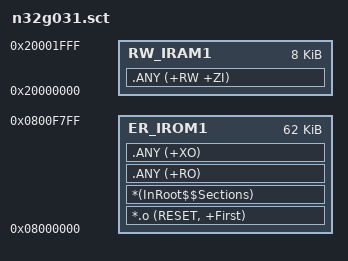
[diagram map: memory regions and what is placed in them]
; N32G031 64KB Flash 0x08000000‑0x0800FFFF
; 主程序使用：0x08000000 ~ 0x0800F7FF (62KB)
; 参数保留页：0x0800F800 ~ 0x0800FFFF （2KB，禁止放代码）
LR_IROM1 0x08000000  0x0000F800  {    
  ER_IROM1 0x08000000  0x0000F800  { 
   *.o (RESET, +First)
   *(InRoot$$Sections)
   .ANY (+RO)
   .ANY (+XO)
  }
  RW_IRAM1 0x20000000  0x00002000  {  ;8KB SRAM
   .ANY (+RW +ZI)
  }
}
; 专门预留参数存储页，没有任何执行域，链接器不会往这里烧任何代码/常量
LR_PARAM_STORAGE 0x0800F800 0x00000800 {
}
